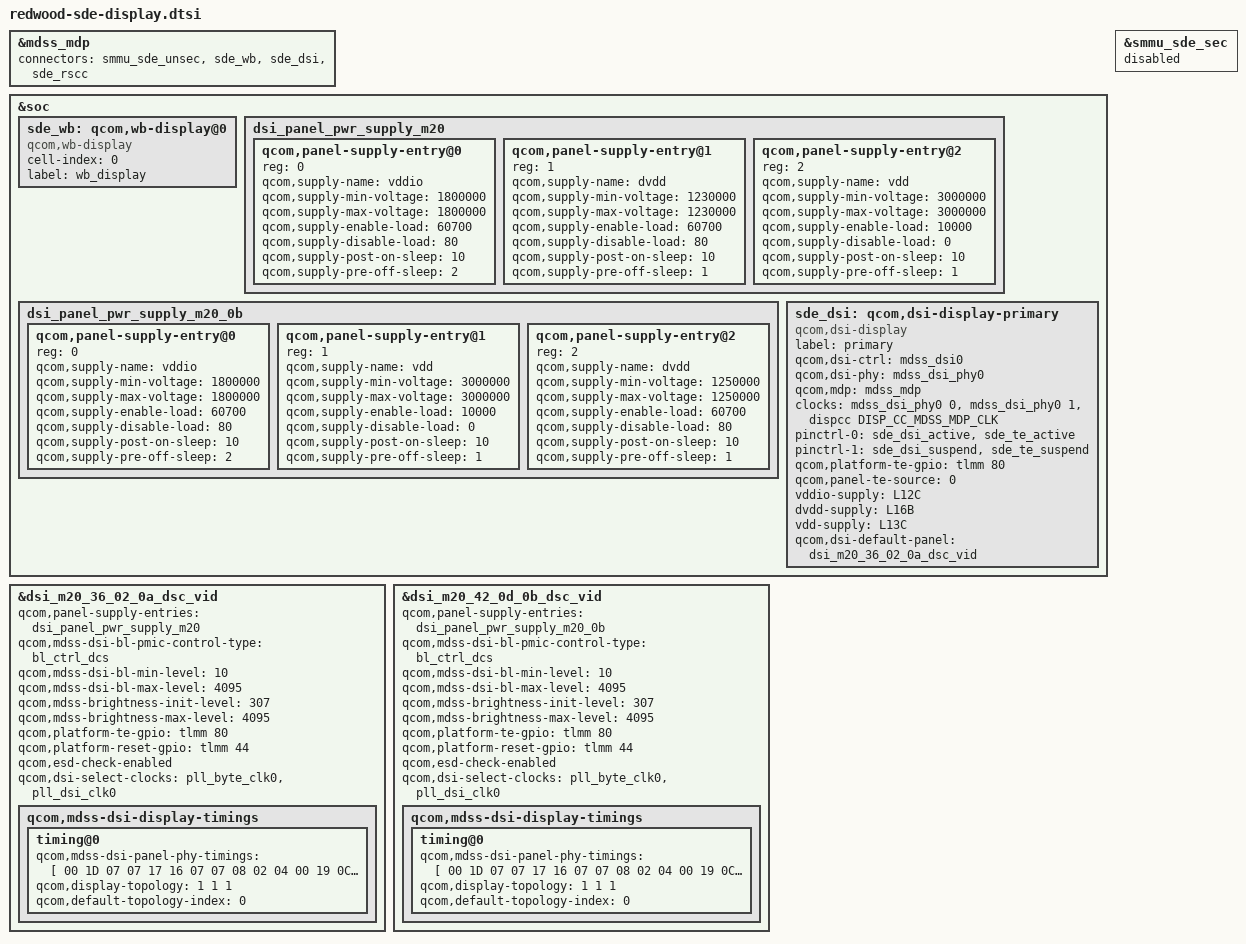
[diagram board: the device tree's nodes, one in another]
// Written by Divyanshu-Modi <Atom-X-Devs https://github.com/Atom-X-Devs>

#include <dt-bindings/clock/mdss-5nm-pll-clk.h>
#include <dt-bindings/clock/qcom,dispcc-sc7280.h>
#include "dsi-panel-m20-36-02-0a-dsc-vid.dtsi"
#include "dsi-panel-m20-42-0d-0b-dsc-vid.dtsi"

&mdss_mdp {
	connectors = <&smmu_sde_unsec &sde_wb &sde_dsi &sde_rscc>;
};

&soc {
	sde_wb: qcom,wb-display@0 {
		compatible = "qcom,wb-display";
		cell-index = <0>;
		label = "wb_display";
	};

	dsi_panel_pwr_supply_m20: dsi_panel_pwr_supply_m20 {
		#address-cells = <1>;
		#size-cells = <0>;

		qcom,panel-supply-entry@0 {
			reg = <0>;
			qcom,supply-name = "vddio";
			qcom,supply-min-voltage = <1800000>;
			qcom,supply-max-voltage = <1800000>;
			qcom,supply-enable-load = <60700>;
			qcom,supply-disable-load = <80>;
			qcom,supply-post-on-sleep = <10>;
			qcom,supply-pre-off-sleep = <2>;
		};

		qcom,panel-supply-entry@1 {
			reg = <1>;
			qcom,supply-name = "dvdd";
			qcom,supply-min-voltage = <1230000>;
			qcom,supply-max-voltage = <1230000>;
			qcom,supply-enable-load = <60700>;
			qcom,supply-disable-load = <80>;
			qcom,supply-post-on-sleep = <10>;
			qcom,supply-pre-off-sleep = <1>;
		};

		qcom,panel-supply-entry@2 {
			reg = <2>;
			qcom,supply-name = "vdd";
			qcom,supply-min-voltage = <3000000>;
			qcom,supply-max-voltage = <3000000>;
			qcom,supply-enable-load = <10000>;
			qcom,supply-disable-load = <0>;
			qcom,supply-post-on-sleep = <10>;
			qcom,supply-pre-off-sleep = <1>;
		};
	};

	dsi_panel_pwr_supply_m20_0b: dsi_panel_pwr_supply_m20_0b {
		#address-cells = <1>;
		#size-cells = <0>;

		qcom,panel-supply-entry@0 {
			reg = <0>;
			qcom,supply-name = "vddio";
			qcom,supply-min-voltage = <1800000>;
			qcom,supply-max-voltage = <1800000>;
			qcom,supply-enable-load = <60700>;
			qcom,supply-disable-load = <80>;
			qcom,supply-post-on-sleep = <10>;
			qcom,supply-pre-off-sleep = <2>;
		};

		qcom,panel-supply-entry@1 {
			reg = <1>;
			qcom,supply-name = "vdd";
			qcom,supply-min-voltage = <3000000>;
			qcom,supply-max-voltage = <3000000>;
			qcom,supply-enable-load = <10000>;
			qcom,supply-disable-load = <0>;
			qcom,supply-post-on-sleep = <10>;
			qcom,supply-pre-off-sleep = <1>;
		};

		qcom,panel-supply-entry@2 {
			reg = <2>;
			qcom,supply-name = "dvdd";
			qcom,supply-min-voltage = <1250000>;
			qcom,supply-max-voltage = <1250000>;
			qcom,supply-enable-load = <60700>;
			qcom,supply-disable-load = <80>;
			qcom,supply-post-on-sleep = <10>;
			qcom,supply-pre-off-sleep = <1>;
		};

	};

	sde_dsi: qcom,dsi-display-primary {
		compatible = "qcom,dsi-display";
		label = "primary";

		qcom,dsi-ctrl = <&mdss_dsi0>;
		qcom,dsi-phy = <&mdss_dsi_phy0>;
		qcom,mdp = <&mdss_mdp>;

		/*
		 * The 5nm PLL in the 6.12 display driver registers just the byte
		 * and DSI clocks, as cells 0 and 1 of the PHY.
		 */
		clocks = <&mdss_dsi_phy0 0>,
			<&mdss_dsi_phy0 1>,
			/*
			 * Not used by dsi_display; it keeps the display clock
			 * controller from syncing state before the splash is
			 * handed over.
			 */
			<&dispcc DISP_CC_MDSS_MDP_CLK>;
		clock-names = "pll_byte_clk0", "pll_dsi_clk0", "mdp_core_clk";

		pinctrl-names = "panel_active", "panel_suspend";
		pinctrl-0 = <&sde_dsi_active &sde_te_active>;
		pinctrl-1 = <&sde_dsi_suspend &sde_te_suspend>;
		qcom,platform-te-gpio = <&tlmm 80 0>;
		qcom,panel-te-source = <0>;

		vddio-supply = <&L12C>;
		dvdd-supply = <&L16B>;
		vdd-supply = <&L13C>;

		qcom,dsi-default-panel = <&dsi_m20_36_02_0a_dsc_vid>;
	};
};

&dsi_m20_36_02_0a_dsc_vid {
	qcom,panel-supply-entries = <&dsi_panel_pwr_supply_m20>;
	qcom,mdss-dsi-bl-pmic-control-type = "bl_ctrl_dcs";
	qcom,mdss-dsi-bl-min-level = <10>;
	qcom,mdss-dsi-bl-max-level = <4095>;
	qcom,mdss-brightness-init-level = <307>;
	qcom,mdss-brightness-max-level = <4095>;
	qcom,platform-te-gpio = <&tlmm 80 0>;
	qcom,platform-reset-gpio = <&tlmm 44 0>;
	qcom,esd-check-enabled;

	qcom,dsi-select-clocks = "pll_byte_clk0", "pll_dsi_clk0";

	qcom,mdss-dsi-display-timings {
		/* 120 Hz */
		timing@0 {
			qcom,mdss-dsi-panel-phy-timings = [
				00 1D 07 07 17 16 07
				07 08 02 04 00 19 0C
			];
			qcom,display-topology = <1 1 1>;
			qcom,default-topology-index = <0>;
		};
	};
};

&dsi_m20_42_0d_0b_dsc_vid {
	qcom,panel-supply-entries = <&dsi_panel_pwr_supply_m20_0b>;
	qcom,mdss-dsi-bl-pmic-control-type = "bl_ctrl_dcs";
	qcom,mdss-dsi-bl-min-level = <10>;
	qcom,mdss-dsi-bl-max-level = <4095>;
	qcom,mdss-brightness-init-level = <307>;
	qcom,mdss-brightness-max-level = <4095>;
	qcom,platform-te-gpio = <&tlmm 80 0>;
	qcom,platform-reset-gpio = <&tlmm 44 0>;
	qcom,esd-check-enabled;

	qcom,dsi-select-clocks = "pll_byte_clk0", "pll_dsi_clk0";

	qcom,mdss-dsi-display-timings {
		/* 120 Hz */
		timing@0 {
			qcom,mdss-dsi-panel-phy-timings = [
				00 1D 07 07 17 16 07
				07 08 02 04 00 19 0C
			];
			qcom,display-topology = <1 1 1>;
			qcom,default-topology-index = <0>;
		};
	};
};

/*
 * Setting up the secure display context bank hangs on redwood's firmware
 * with the 6.12 driver; leave secure display out until that is understood.
 */
&smmu_sde_sec {
	status = "disabled";
};
